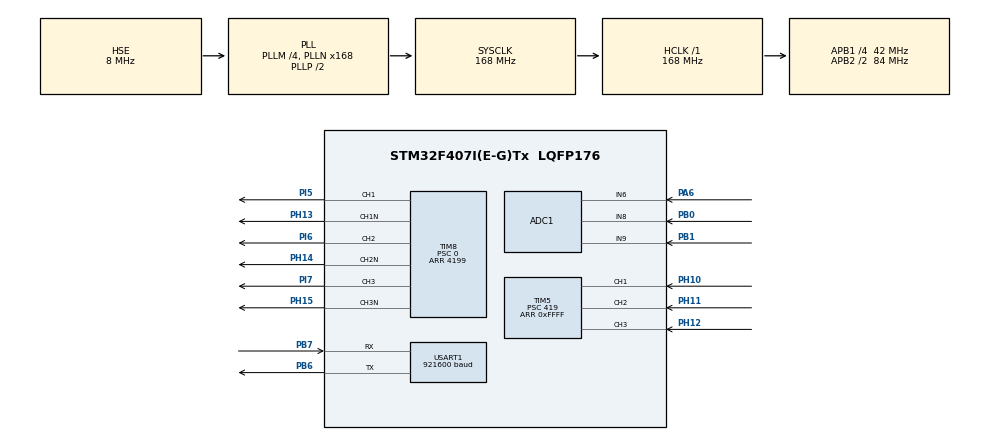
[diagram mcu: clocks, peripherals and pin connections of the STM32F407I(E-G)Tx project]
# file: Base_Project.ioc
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ADC1.Channel-0\#ChannelRegularConversion=ADC_CHANNEL_6
ADC1.Channel-1\#ChannelInjectedConversion=ADC_CHANNEL_6
ADC1.Channel-2\#ChannelInjectedConversion=ADC_CHANNEL_8
ADC1.Channel-3\#ChannelInjectedConversion=ADC_CHANNEL_9
ADC1.ContinuousConvMode=DISABLE
ADC1.DiscontinuousConvMode=DISABLE
ADC1.ExternalTrigInjecConv=ADC_EXTERNALTRIGINJECCONV_T8_CC4
ADC1.InjNumberOfConversion=3
ADC1.InjectedOffset-1\#ChannelInjectedConversion=0
ADC1.InjectedOffset-2\#ChannelInjectedConversion=0
ADC1.InjectedOffset-3\#ChannelInjectedConversion=0
ADC1.InjectedRank-1\#ChannelInjectedConversion=1
ADC1.InjectedRank-2\#ChannelInjectedConversion=2
ADC1.InjectedRank-3\#ChannelInjectedConversion=3
ADC1.NbrOfConversion=1
ADC1.NbrOfConversionFlag=1
ADC1.Rank-0\#ChannelRegularConversion=1
ADC1.SamplingTime-0\#ChannelRegularConversion=ADC_SAMPLETIME_3CYCLES
ADC1.SamplingTime-1\#ChannelInjectedConversion=ADC_SAMPLETIME_3CYCLES
ADC1.SamplingTime-2\#ChannelInjectedConversion=ADC_SAMPLETIME_3CYCLES
ADC1.SamplingTime-3\#ChannelInjectedConversion=ADC_SAMPLETIME_3CYCLES
ADC1.ScanConvMode=ENABLE
ADC1.master=1
Dma.Request0=USART1_TX
Dma.Request1=USART1_RX
Dma.USART1_RX.1.Direction=DMA_PERIPH_TO_MEMORY
Dma.USART1_RX.1.FIFOMode=DMA_FIFOMODE_DISABLE
Dma.USART1_RX.1.Instance=DMA2_Stream2
Dma.USART1_RX.1.MemDataAlignment=DMA_MDATAALIGN_BYTE
Dma.USART1_RX.1.MemInc=DMA_MINC_ENABLE
Dma.USART1_RX.1.Mode=DMA_NORMAL
Dma.USART1_RX.1.PeriphDataAlignment=DMA_PDATAALIGN_BYTE
Dma.USART1_RX.1.PeriphInc=DMA_PINC_DISABLE
Dma.USART1_RX.1.Priority=DMA_PRIORITY_LOW
Dma.USART1_TX.0.Direction=DMA_MEMORY_TO_PERIPH
Dma.USART1_TX.0.FIFOMode=DMA_FIFOMODE_DISABLE
Dma.USART1_TX.0.Instance=DMA2_Stream7
Dma.USART1_TX.0.MemDataAlignment=DMA_MDATAALIGN_BYTE
Dma.USART1_TX.0.MemInc=DMA_MINC_ENABLE
Dma.USART1_TX.0.Mode=DMA_NORMAL
Dma.USART1_TX.0.PeriphDataAlignment=DMA_PDATAALIGN_BYTE
Dma.USART1_TX.0.PeriphInc=DMA_PINC_DISABLE
Dma.USART1_TX.0.Priority=DMA_PRIORITY_LOW
Mcu.Family=STM32F4
Mcu.Name=STM32F407I(E-G)Tx
Mcu.Package=LQFP176
NVIC.ADC_IRQn=true\:0\:0\:false\:false\:true\:true\:true\:true
NVIC.DMA2_Stream2_IRQn=true\:2\:0\:true\:false\:true\:false\:true\:true
NVIC.DMA2_Stream7_IRQn=true\:2\:0\:true\:false\:true\:false\:true\:true
NVIC.PriorityGroup=NVIC_PRIORITYGROUP_2
NVIC.TIM5_IRQn=true\:1\:0\:true\:false\:true\:true\:true\:true
NVIC.TIM8_UP_TIM13_IRQn=true\:3\:0\:true\:false\:true\:true\:true\:true
NVIC.USART1_IRQn=true\:2\:1\:true\:false\:true\:true\:true\:true
PA13.Mode=Serial_Wire
PA13.Signal=SYS_JTMS-SWDIO
PA14.Mode=Serial_Wire
PA14.Signal=SYS_JTCK-SWCLK
PA6.Signal=ADCx_IN6
PB0.Signal=ADCx_IN8
PB1.Signal=ADCx_IN9
PB6.GPIO_PuPd=GPIO_NOPULL
PB6.GPIO_Speed=GPIO_SPEED_FREQ_HIGH
PB6.Mode=Asynchronous
PB6.Signal=USART1_TX
PB7.GPIO_PuPd=GPIO_PULLUP
PB7.GPIO_Speed=GPIO_SPEED_FREQ_HIGH
PB7.Mode=Asynchronous
PB7.Signal=USART1_RX
PH0-OSC_IN.Mode=HSE-External-Oscillator
PH0-OSC_IN.Signal=RCC_OSC_IN
PH1-OSC_OUT.Mode=HSE-External-Oscillator
PH1-OSC_OUT.Signal=RCC_OSC_OUT
PH10.GPIO_PuPd=GPIO_PULLUP
PH10.GPIO_Speed=GPIO_SPEED_FREQ_HIGH
PH10.Signal=S_TIM5_CH1
PH11.GPIO_PuPd=GPIO_PULLUP
PH11.GPIO_Speed=GPIO_SPEED_FREQ_HIGH
PH11.Signal=S_TIM5_CH2
PH12.GPIO_PuPd=GPIO_PULLUP
PH12.GPIO_Speed=GPIO_SPEED_FREQ_HIGH
PH12.Signal=S_TIM5_CH3
PH13.Mode=PWM Generation1 CH1 CH1N
PH13.Signal=TIM8_CH1N
PH14.Mode=PWM Generation2 CH2 CH2N
PH14.Signal=TIM8_CH2N
PH15.Mode=PWM Generation3 CH3 CH3N
PH15.Signal=TIM8_CH3N
PI5.Signal=S_TIM8_CH1
PI6.Signal=S_TIM8_CH2
PI7.Signal=S_TIM8_CH3
ProjectManager.HeapSize=0x200
ProjectManager.StackSize=0x400
ProjectManager.TargetToolchain=MDK-ARM V5.32
RCC.48MHZClocksFreq_Value=84000000
RCC.AHBFreq_Value=168000000
RCC.APB1CLKDivider=RCC_HCLK_DIV4
RCC.APB1Freq_Value=42000000
RCC.APB1TimFreq_Value=84000000
RCC.APB2CLKDivider=RCC_HCLK_DIV2
RCC.APB2Freq_Value=84000000
RCC.APB2TimFreq_Value=168000000
RCC.CortexFreq_Value=168000000
RCC.HCLKFreq_Value=168000000
RCC.HSE_VALUE=8000000
RCC.HSI_VALUE=16000000
RCC.LSE_VALUE=32768
RCC.PLLM=4
RCC.PLLN=168
RCC.PLLSourceVirtual=RCC_PLLSOURCE_HSE
RCC.SYSCLKFreq_VALUE=168000000
RCC.SYSCLKSource=RCC_SYSCLKSOURCE_PLLCLK
RCC.VCOOutputFreq_Value=336000000
SH.ADCx_IN6.0=ADC1_IN6,IN6
SH.ADCx_IN8.0=ADC1_IN8,IN8
SH.ADCx_IN9.0=ADC1_IN9,IN9
SH.S_TIM5_CH1.0=TIM5_CH1,Xored_Inputs_Hall_Sensor_Interface
SH.S_TIM5_CH2.0=TIM5_CH2,Xored_Inputs_Hall_Sensor_Interface
SH.S_TIM5_CH3.0=TIM5_CH3,Xored_Inputs_Hall_Sensor_Interface
SH.S_TIM8_CH1.0=TIM8_CH1,PWM Generation1 CH1 CH1N
SH.S_TIM8_CH2.0=TIM8_CH2,PWM Generation2 CH2 CH2N
SH.S_TIM8_CH3.0=TIM8_CH3,PWM Generation3 CH3 CH3N
TIM5.AutoReloadPreload=TIM_AUTORELOAD_PRELOAD_ENABLE
TIM5.Commutation_Delay=0x06
TIM5.IC1Filter=0x0F
TIM5.Period=0xFFFF
TIM5.Prescaler=419
TIM8.AutoReloadPreload=TIM_AUTORELOAD_PRELOAD_ENABLE
TIM8.AutomaticOutput=TIM_AUTOMATICOUTPUT_ENABLE
TIM8.Channel-PWM\ Generation1\ CH1\ CH1N=TIM_CHANNEL_1
TIM8.Channel-PWM\ Generation2\ CH2\ CH2N=TIM_CHANNEL_2
TIM8.Channel-PWM\ Generation3\ CH3\ CH3N=TIM_CHANNEL_3
TIM8.Channel-PWM\ Generation4\ No\ Output=TIM_CHANNEL_4
TIM8.CounterMode=TIM_COUNTERMODE_CENTERALIGNED1
TIM8.DeadTime=60
TIM8.OCMode_PWM-PWM\ Generation4\ No\ Output=TIM_OCMODE_PWM2
TIM8.OCPolarity_4=TIM_OCPOLARITY_HIGH
TIM8.Period=4199
TIM8.Prescaler=0
TIM8.Pulse-PWM\ Generation4\ No\ Output=4150
USART1.BaudRate=921600
USART1.VirtualMode=VM_ASYNC
VP_TIM8_VS_ClockSourceINT.Mode=Internal
VP_TIM8_VS_no_output4.Mode=PWM Generation4 No Output
board=custom

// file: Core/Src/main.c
/* USER CODE BEGIN Header */
/**
  ******************************************************************************
  * @file           : main.c
  * @brief          : Main program body
  ******************************************************************************
  * @attention
  *
  * Copyright (c) 2026 STMicroelectronics.
  * All rights reserved.
  *
  * This software is licensed under terms that can be found in the LICENSE file
  * in the root directory of this software component.
  * If no LICENSE file comes with this software, it is provided AS-IS.
  *
  ******************************************************************************
  */
/* USER CODE END Header */
#include "main.h"
#include "adc.h"
#include "dma.h"
#include "tim.h"
#include "usart.h"
#include "gpio.h"

/* USER CODE BEGIN Includes */
#include "string.h"

#include "Motor_Config.h"
#include "StateMachine.h"

#include "bsp_usart.h"

#include "VOFA.h"

/* USER CODE END Includes */

void SystemClock_Config(void);

int main(void)
{

  /* MCU Configuration--------------------------------------------------------*/

  /* Reset of all peripherals, Initializes the Flash interface and the Systick. */
  HAL_Init();

  /* Configure the system clock */
  SystemClock_Config();

  /* Initialize all configured peripherals */
  MX_GPIO_Init();
  MX_DMA_Init();
  MX_USART1_UART_Init();
  MX_TIM8_Init();
  MX_TIM5_Init();
  MX_ADC1_Init();
  /* USER CODE BEGIN 2 */
  /*电机状态机初始化*/
  Motor_StateMachine_Init(&MotorBLDC);

  /* USER CODE END 2 */

  /* Infinite loop */
  /* USER CODE BEGIN WHILE */
  while (1)
  {

    VofaJustWater_Send();

    /* USER CODE END WHILE */

  }
}

void SystemClock_Config(void)
{
  RCC_OscInitTypeDef RCC_OscInitStruct = {0};
  RCC_ClkInitTypeDef RCC_ClkInitStruct = {0};

  /** Configure the main internal regulator output voltage
  */
  __HAL_RCC_PWR_CLK_ENABLE();
  __HAL_PWR_VOLTAGESCALING_CONFIG(PWR_REGULATOR_VOLTAGE_SCALE1);

  /** Initializes the RCC Oscillators according to the specified parameters
  * in the RCC_OscInitTypeDef structure.
  */
  RCC_OscInitStruct.OscillatorType = RCC_OSCILLATORTYPE_HSE;
  RCC_OscInitStruct.HSEState = RCC_HSE_ON;
  RCC_OscInitStruct.PLL.PLLState = RCC_PLL_ON;
  RCC_OscInitStruct.PLL.PLLSource = RCC_PLLSOURCE_HSE;
  RCC_OscInitStruct.PLL.PLLM = 4;
  RCC_OscInitStruct.PLL.PLLN = 168;
  RCC_OscInitStruct.PLL.PLLP = RCC_PLLP_DIV2;
  RCC_OscInitStruct.PLL.PLLQ = 4;
  if (HAL_RCC_OscConfig(&RCC_OscInitStruct) != HAL_OK)
  {
    Error_Handler();
  }

  /** Initializes the CPU, AHB and APB buses clocks
  */
  RCC_ClkInitStruct.ClockType = RCC_CLOCKTYPE_HCLK|RCC_CLOCKTYPE_SYSCLK
                              |RCC_CLOCKTYPE_PCLK1|RCC_CLOCKTYPE_PCLK2;
  RCC_ClkInitStruct.SYSCLKSource = RCC_SYSCLKSOURCE_PLLCLK;
  RCC_ClkInitStruct.AHBCLKDivider = RCC_SYSCLK_DIV1;
  RCC_ClkInitStruct.APB1CLKDivider = RCC_HCLK_DIV4;
  RCC_ClkInitStruct.APB2CLKDivider = RCC_HCLK_DIV2;

  if (HAL_RCC_ClockConfig(&RCC_ClkInitStruct, FLASH_LATENCY_5) != HAL_OK)
  {
    Error_Handler();
  }
}

/* USER CODE BEGIN 4 */
/* HAL_UART_RxCpltCallback 已在 VOFA.c 实现（解析目标转速命令），此处不再重复定义 */
/* USER CODE END 4 */

void Error_Handler(void)
{
  __disable_irq();
  while (1)
  {
  }
}
